# mc200 register map
Registers are 32-bit, access not given, no defined reset value unless marked. A register's access mark holds for its fields unless they carry their own. Addresses are absolute; registers are grouped by the start of their names; [hi:lo] are bit positions.

## RC32M
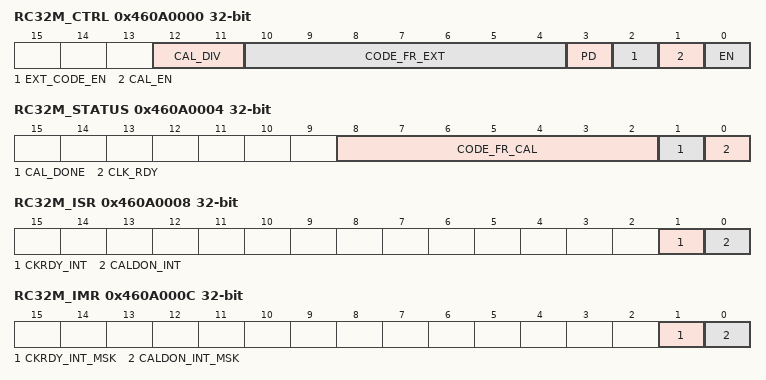
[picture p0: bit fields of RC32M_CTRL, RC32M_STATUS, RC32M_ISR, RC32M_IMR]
0x460A0000 RC32M_CTRL
  [12:11] CAL_DIV, [10:4] CODE_FR_EXT, [3] PD, [2] EXT_CODE_EN, [1] CAL_EN, [0] EN
0x460A0004 RC32M_STATUS
  [8:2] CODE_FR_CAL, [1] CAL_DONE, [0] CLK_RDY
0x460A0008 RC32M_ISR
  [1] CKRDY_INT, [0] CALDON_INT
0x460A000C RC32M_IMR
  [1] CKRDY_INT_MSK, [0] CALDON_INT_MSK
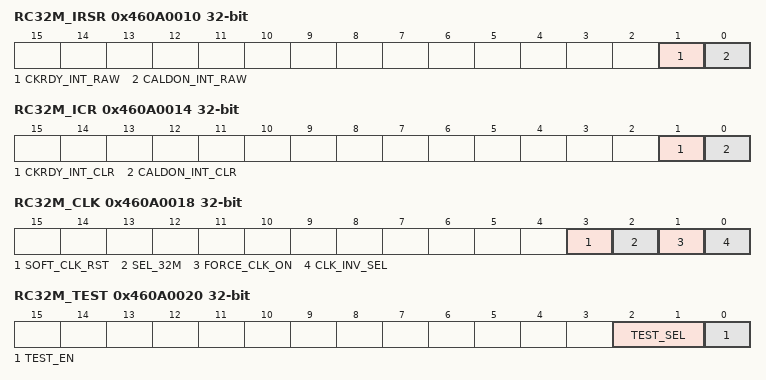
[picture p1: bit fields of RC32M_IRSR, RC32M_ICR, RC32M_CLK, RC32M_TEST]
0x460A0010 RC32M_IRSR
  [1] CKRDY_INT_RAW, [0] CALDON_INT_RAW
0x460A0014 RC32M_ICR
  [1] CKRDY_INT_CLR, [0] CALDON_INT_CLR
0x460A0018 RC32M_CLK
  [3] SOFT_CLK_RST, [2] SEL_32M, [1] FORCE_CLK_ON, [0] CLK_INV_SEL
0x460A001C RC32M_RST
  [0] SOFT_RST
0x460A0020 RC32M_TEST
  [2:1] TEST_SEL, [0] TEST_EN
0x460A0024 RC32M_RSVD

## ADC0
0x460B0000 ADC0_PWR
  [0] GLOBAL_EN
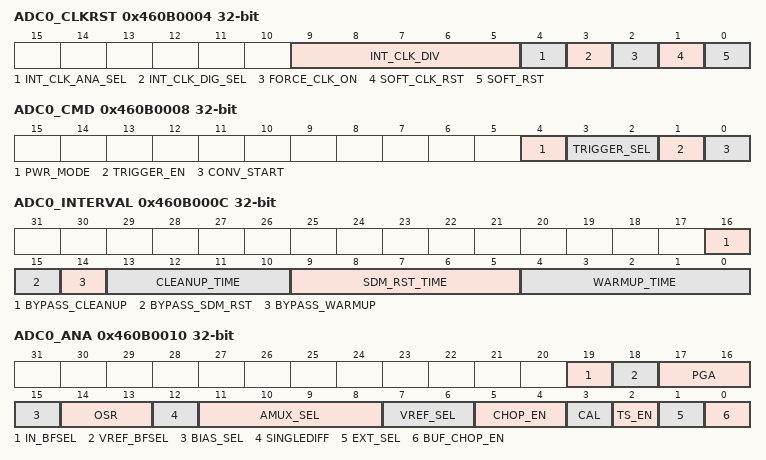
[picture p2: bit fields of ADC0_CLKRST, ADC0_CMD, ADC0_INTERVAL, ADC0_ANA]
0x460B0004 ADC0_CLKRST
  [9:5] INT_CLK_DIV, [4] INT_CLK_ANA_SEL, [3] INT_CLK_DIG_SEL, [2] FORCE_CLK_ON, [1] SOFT_CLK_RST, [0] SOFT_RST
0x460B0008 ADC0_CMD
  [4] PWR_MODE, [3:2] TRIGGER_SEL, [1] TRIGGER_EN, [0] CONV_START
0x460B000C ADC0_INTERVAL
  [16] BYPASS_CLEANUP, [15] BYPASS_SDM_RST, [14] BYPASS_WARMUP, [13:10] CLEANUP_TIME, [9:5] SDM_RST_TIME, [4:0] WARMUP_TIME
0x460B0010 ADC0_ANA
  [19] IN_BFSEL, [18] VREF_BFSEL, [17:16] PGA, [15] BIAS_SEL, [14:13] OSR, [12] SINGLEDIFF, [11:8] AMUX_SEL, [7:6] VREF_SEL, [5:4] CHOP_EN, [3] CAL, [2] TS_EN, [1] EXT_SEL, [0] BUF_CHOP_EN
0x460B0014 ADC0_DMA
  [0] DMA_EN
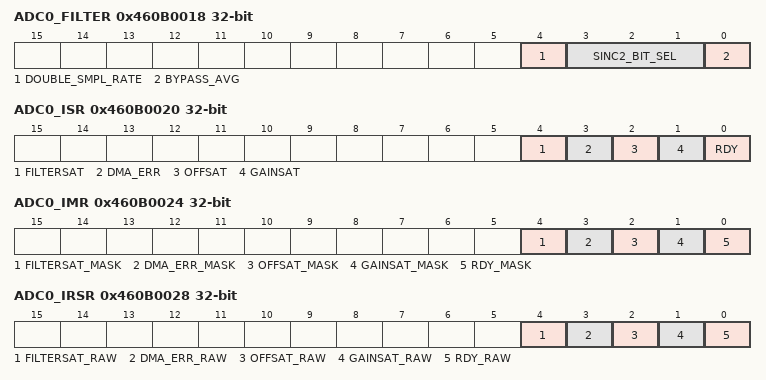
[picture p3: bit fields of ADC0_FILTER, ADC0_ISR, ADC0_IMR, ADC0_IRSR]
0x460B0018 ADC0_FILTER
  [4] DOUBLE_SMPL_RATE, [3:1] SINC2_BIT_SEL, [0] BYPASS_AVG
0x460B001C ADC0_STATUS
  [0] ACT
0x460B0020 ADC0_ISR
  [4] FILTERSAT, [3] DMA_ERR, [2] OFFSAT, [1] GAINSAT, [0] RDY
0x460B0024 ADC0_IMR
  [4] FILTERSAT_MASK, [3] DMA_ERR_MASK, [2] OFFSAT_MASK, [1] GAINSAT_MASK, [0] RDY_MASK
0x460B0028 ADC0_IRSR
  [4] FILTERSAT_RAW, [3] DMA_ERR_RAW, [2] OFFSAT_RAW, [1] GAINSAT_RAW, [0] RDY_RAW
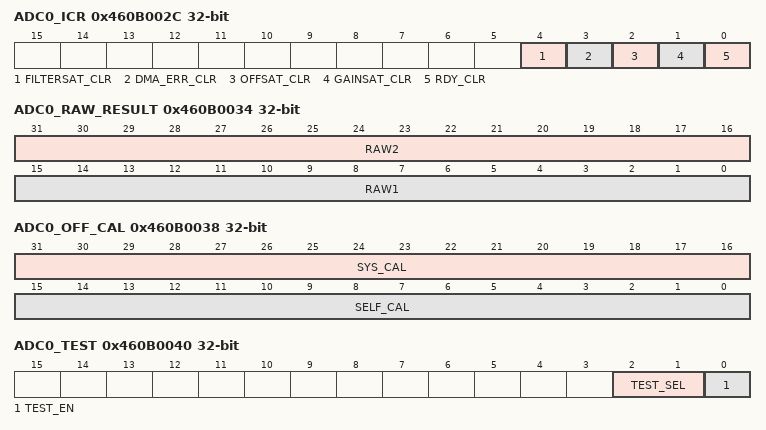
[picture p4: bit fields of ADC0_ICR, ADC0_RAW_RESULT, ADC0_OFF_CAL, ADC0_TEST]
0x460B002C ADC0_ICR
  [4] FILTERSAT_CLR, [3] DMA_ERR_CLR, [2] OFFSAT_CLR, [1] GAINSAT_CLR, [0] RDY_CLR
0x460B0030 ADC0_RESULT
  [15:0] DATA
0x460B0034 ADC0_RAW_RESULT
  [31:16] RAW2, [15:0] RAW1
0x460B0038 ADC0_OFF_CAL
  [31:16] SYS_CAL, [15:0] SELF_CAL
0x460B003C ADC0_GAIN_CAL
  [15:0] GAIN_CAL
0x460B0040 ADC0_TEST
  [2:1] TEST_SEL, [0] TEST_EN
0x460B0044 ADC0_RSVD

## ADC1
0x460B0100 ADC1_PWR
  [0] GLOBAL_EN
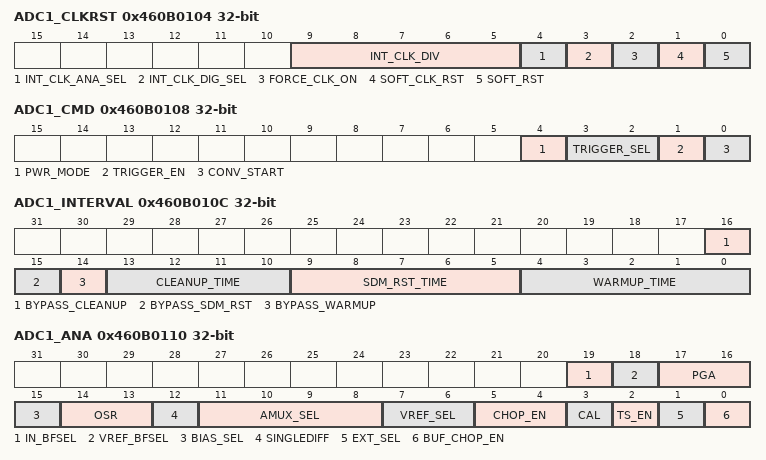
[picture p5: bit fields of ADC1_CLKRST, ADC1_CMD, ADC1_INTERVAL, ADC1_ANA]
0x460B0104 ADC1_CLKRST
  [9:5] INT_CLK_DIV, [4] INT_CLK_ANA_SEL, [3] INT_CLK_DIG_SEL, [2] FORCE_CLK_ON, [1] SOFT_CLK_RST, [0] SOFT_RST
0x460B0108 ADC1_CMD
  [4] PWR_MODE, [3:2] TRIGGER_SEL, [1] TRIGGER_EN, [0] CONV_START
0x460B010C ADC1_INTERVAL
  [16] BYPASS_CLEANUP, [15] BYPASS_SDM_RST, [14] BYPASS_WARMUP, [13:10] CLEANUP_TIME, [9:5] SDM_RST_TIME, [4:0] WARMUP_TIME
0x460B0110 ADC1_ANA
  [19] IN_BFSEL, [18] VREF_BFSEL, [17:16] PGA, [15] BIAS_SEL, [14:13] OSR, [12] SINGLEDIFF, [11:8] AMUX_SEL, [7:6] VREF_SEL, [5:4] CHOP_EN, [3] CAL, [2] TS_EN, [1] EXT_SEL, [0] BUF_CHOP_EN
0x460B0114 ADC1_DMA
  [0] DMA_EN
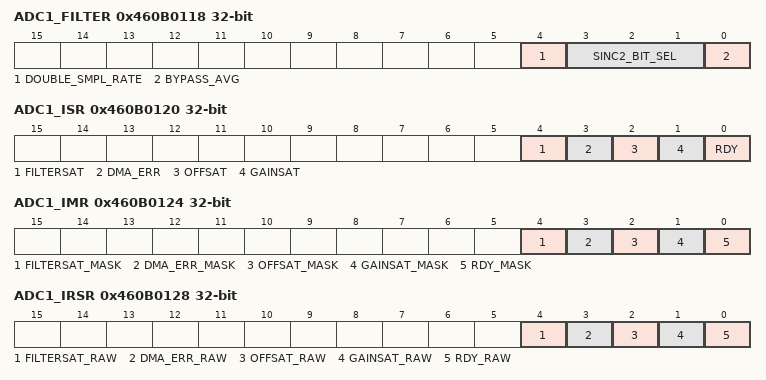
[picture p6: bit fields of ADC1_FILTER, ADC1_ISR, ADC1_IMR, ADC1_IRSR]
0x460B0118 ADC1_FILTER
  [4] DOUBLE_SMPL_RATE, [3:1] SINC2_BIT_SEL, [0] BYPASS_AVG
0x460B011C ADC1_STATUS
  [0] ACT
0x460B0120 ADC1_ISR
  [4] FILTERSAT, [3] DMA_ERR, [2] OFFSAT, [1] GAINSAT, [0] RDY
0x460B0124 ADC1_IMR
  [4] FILTERSAT_MASK, [3] DMA_ERR_MASK, [2] OFFSAT_MASK, [1] GAINSAT_MASK, [0] RDY_MASK
0x460B0128 ADC1_IRSR
  [4] FILTERSAT_RAW, [3] DMA_ERR_RAW, [2] OFFSAT_RAW, [1] GAINSAT_RAW, [0] RDY_RAW
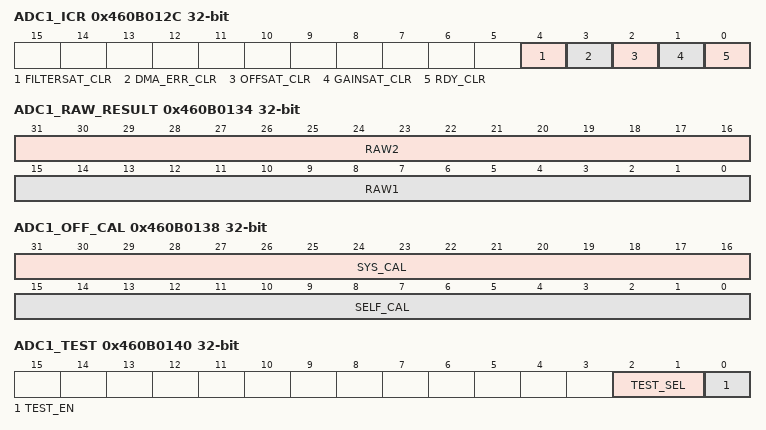
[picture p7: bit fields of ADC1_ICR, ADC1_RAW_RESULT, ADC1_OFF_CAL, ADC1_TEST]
0x460B012C ADC1_ICR
  [4] FILTERSAT_CLR, [3] DMA_ERR_CLR, [2] OFFSAT_CLR, [1] GAINSAT_CLR, [0] RDY_CLR
0x460B0130 ADC1_RESULT
  [15:0] DATA
0x460B0134 ADC1_RAW_RESULT
  [31:16] RAW2, [15:0] RAW1
0x460B0138 ADC1_OFF_CAL
  [31:16] SYS_CAL, [15:0] SELF_CAL
0x460B013C ADC1_GAIN_CAL
  [15:0] GAIN_CAL
0x460B0140 ADC1_TEST
  [2:1] TEST_SEL, [0] TEST_EN
0x460B0144 ADC1_RSVD

## DAC
0x460B0200 DAC_CTRL
  [0] REF_SEL
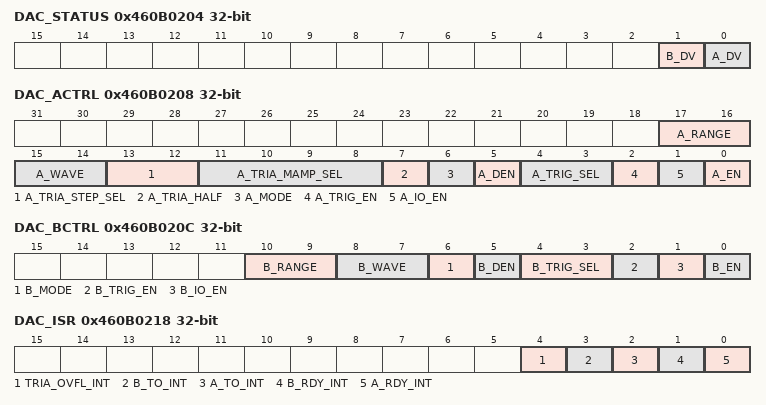
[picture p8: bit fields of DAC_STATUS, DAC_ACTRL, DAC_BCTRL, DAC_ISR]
0x460B0204 DAC_STATUS
  [1] B_DV, [0] A_DV
0x460B0208 DAC_ACTRL
  [17:16] A_RANGE, [15:14] A_WAVE, [13:12] A_TRIA_STEP_SEL, [11:8] A_TRIA_MAMP_SEL, [7] A_TRIA_HALF, [6] A_MODE, [5] A_DEN, [4:3] A_TRIG_SEL, [2] A_TRIG_EN, [1] A_IO_EN, [0] A_EN
0x460B020C DAC_BCTRL
  [10:9] B_RANGE, [8:7] B_WAVE, [6] B_MODE, [5] B_DEN, [4:3] B_TRIG_SEL, [2] B_TRIG_EN, [1] B_IO_EN, [0] B_EN
0x460B0210 DAC_ADATA
  [9:0] A_DATA
0x460B0214 DAC_BDATA
  [9:0] B_DATA
0x460B0218 DAC_ISR
  [4] TRIA_OVFL_INT, [3] B_TO_INT, [2] A_TO_INT, [1] B_RDY_INT, [0] A_RDY_INT
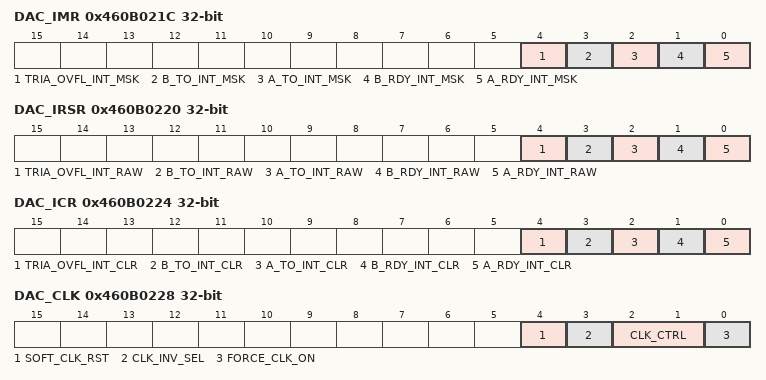
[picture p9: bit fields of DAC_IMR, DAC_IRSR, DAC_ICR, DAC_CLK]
0x460B021C DAC_IMR
  [4] TRIA_OVFL_INT_MSK, [3] B_TO_INT_MSK, [2] A_TO_INT_MSK, [1] B_RDY_INT_MSK, [0] A_RDY_INT_MSK
0x460B0220 DAC_IRSR
  [4] TRIA_OVFL_INT_RAW, [3] B_TO_INT_RAW, [2] A_TO_INT_RAW, [1] B_RDY_INT_RAW, [0] A_RDY_INT_RAW
0x460B0224 DAC_ICR
  [4] TRIA_OVFL_INT_CLR, [3] B_TO_INT_CLR, [2] A_TO_INT_CLR, [1] B_RDY_INT_CLR, [0] A_RDY_INT_CLR
0x460B0228 DAC_CLK
  [4] SOFT_CLK_RST, [3] CLK_INV_SEL, [2:1] CLK_CTRL, [0] FORCE_CLK_ON
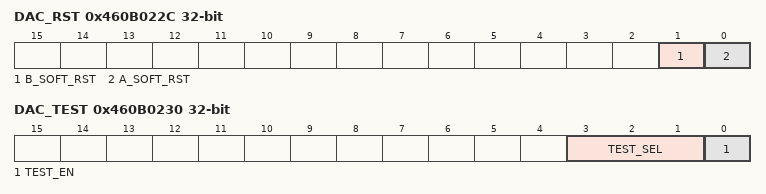
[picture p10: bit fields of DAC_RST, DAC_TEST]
0x460B022C DAC_RST
  [1] B_SOFT_RST, [0] A_SOFT_RST
0x460B0230 DAC_TEST
  [3:1] TEST_SEL, [0] TEST_EN
0x460B0234 DAC_RSVD
